AUTOSAR XML (schema 00053)
standard types defined: uint16, uint16_DataConstr
package /Constants
  constant specification Cabin_Door_PDIO_FL_t_Init: value-spec=fields=[0, 0, 0, 0, 0, 0, 0, 0, 0, 0, 0, 0, 0, 0, 0]
  constant specification GCS_LEFT_2_PDIO_FL_t_Init: value-spec=fields=[0, 0, 0, 0, 0, 0, 0, 0, 0, 0, 0, 0, 0, 0, 0, 0, 0]
package /ComponentTypes
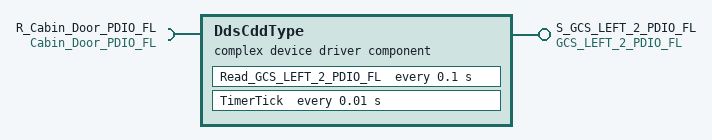
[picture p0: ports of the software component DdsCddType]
  complex device driver sw component type DdsCddType
    require port R_Cabin_Door_PDIO_FL: nonqueued-receiver-com-spec{data-element=Cabin_Door_PDIO_FL_t, init-value=constant-reference=Cabin_Door_PDIO_FL_t_Init}, required-interface=Cabin_Door_PDIO_FL
    provide port S_GCS_LEFT_2_PDIO_FL: nonqueued-sender-com-spec{data-element=GCS_LEFT_2_PDIO_FL_t, init-value=constant-reference=GCS_LEFT_2_PDIO_FL_t_Init}, provided-interface=GCS_LEFT_2_PDIO_FL
    behavior DdsCddType_InternalBehavior: handle-termination-and-restart=NO-SUPPORT
      4 x exclusive area:
        ExclusiveArea_heap
        ExclusiveArea_netio
        ExclusiveArea_system
        ExclusiveArea_tick
      static-memorys:
        data StaticConstantMemory: sw-calibration-access=READ-ONLY, type=uint16
      timing event TMT_DdsCdd_Read_GCS_LEFT_2_PDIO_FL: start-on-event=Read_GCS_LEFT_2_PDIO_FL, offset=0.005, period=0.1
      timing event TMT_DdsCdd_Run: start-on-event=TimerTick, offset=0.002, period=0.01
      data received event DRT_DdsCdd_Write_Cabin_Door_PDIO_FL_Cabin_Door_PDIO_FL_t: start-on-event=Write_Cabin_Door_PDIO_FL, data=R_Cabin_Door_PDIO_FL.Cabin_Door_PDIO_FL_t
      internal trigger occurred event ITOE_DdsRxIndication_DataReception_ITP_DummyCallout: start-on-event=ProcessData, event-source=ITP_DdsCdd_RxIndication
      internal trigger occurred event ITOE_TimerUpdate_ITP_TimerUpdate: start-on-event=TimerUpdate, event-source=ITP_TimerUpdate
      init event InitEvent: start-on-event=Init
      internal trigger occurred event ITOE_Start_ITP_Start: start-on-event=Enable, event-source=ITP_Start
      8 x runnable:
        Read_GCS_LEFT_2_PDIO_FL
          data-send-points:
            access SEND_S_GCS_LEFT_2_PDIO_FL_GCS_LEFT_2_PDIO_FL_t: accessed-variable=S_GCS_LEFT_2_PDIO_FL.GCS_LEFT_2_PDIO_FL_t
        TimerTick: can-enters=[ExclusiveArea_tick, ExclusiveArea_system]
          internal triggering point ITP_TimerUpdate
        Enable: can-enters=[ExclusiveArea_system, ExclusiveArea_heap]
        Write_Cabin_Door_PDIO_FL: can-enters=ExclusiveArea_heap
          data-receive-point-by-arguments:
            access REC_Cabin_Door_PDIO_FL_Cabin_Door_PDIO_FL_t: accessed-variable=R_Cabin_Door_PDIO_FL.Cabin_Door_PDIO_FL_t
        ProcessData
        RxIndication
          internal triggering point ITP_DdsCdd_RxIndication
        TimerUpdate
        Init
          internal triggering point ITP_Start
    symbol props DdsCdd
  swc implementation DdsCddType_Implementation: behavior=DdsCddType_InternalBehavior
    code-descriptors:
      code Default: artifact-descriptors=autosar-engineering-object={short-label=Default, category=SWSRC}
package /PortInterfaces
  sender receiver interface Cabin_Door_PDIO_FL
    data Cabin_Door_PDIO_FL_t: type=Cabin_Door_PDIO_FL_t
  sender receiver interface GCS_LEFT_2_PDIO_FL
    data GCS_LEFT_2_PDIO_FL_t: type=GCS_LEFT_2_PDIO_FL_t
